# ATmega168PA device description
Architecture: AVR8; Family: megaAVR
Registers are 8-bit, access not given, no defined reset value unless marked. A register's access mark holds for its fields unless they carry their own. Offsets are from the block's base; [hi:lo] are bit positions; {n}, {i} and the like mark numbered series.

## TC2 (TC8_ASYNC module) — Timer/Counter, 8-bit Async
Instances: TC2 0x00
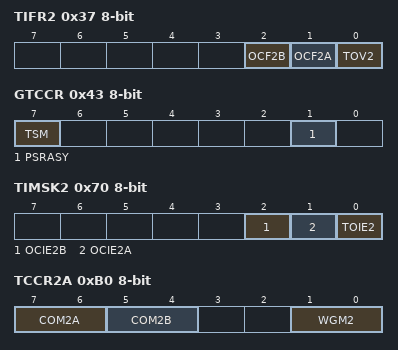
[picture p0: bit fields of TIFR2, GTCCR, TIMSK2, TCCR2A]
0x37 TIFR2 — Timer/Counter Interrupt Flag Register
  [2] OCF2B — Output Compare Flag 2B
  [1] OCF2A — Output Compare Flag 2A
  [0] TOV2 — Timer/Counter2 Overflow Flag
0x43 GTCCR — General Timer Counter Control register
  [7] TSM — Timer/Counter Synchronization Mode
  [1] PSRASY — Prescaler Reset Timer/Counter2
0x70 TIMSK2 — Timer/Counter Interrupt Mask register
  [2] OCIE2B — Timer/Counter2 Output Compare Match B Interrupt Enable
  [1] OCIE2A — Timer/Counter2 Output Compare Match A Interrupt Enable
  [0] TOIE2 — Timer/Counter2 Overflow Interrupt Enable
0xB0 TCCR2A — Timer/Counter2 Control Register A
  [7:6] COM2A — Compare Output Mode bits
  [5:4] COM2B — Compare Output Mode bits
  [1:0] WGM2 — Waveform Genration Mode
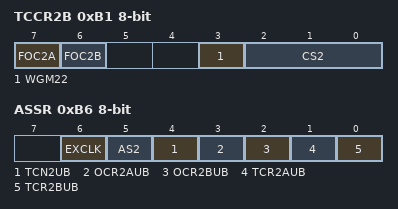
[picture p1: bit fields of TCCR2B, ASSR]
0xB1 TCCR2B — Timer/Counter2 Control Register B
  [7] FOC2A — Force Output Compare A
  [6] FOC2B — Force Output Compare B
  [3] WGM22 — Waveform Generation Mode
  [2:0] CS2 — Clock Select bits
    0=No Clock Source (Stopped); 1=Running, No Prescaling; 2=Running, CLK/8; 3=Running, CLK/32; 4=Running, CLK/64; 5=Running, CLK/128; 6=Running, CLK/256; 7=Running, CLK/1024
0xB2 TCNT2 — Timer/Counter2
0xB3 OCR2A — Timer/Counter2 Output Compare Register A
0xB4 OCR2B — Timer/Counter2 Output Compare Register B
0xB6 ASSR — Asynchronous Status Register
  [6] EXCLK — Enable External Clock Input
  [5] AS2 — Asynchronous Timer/Counter2
  [4] TCN2UB — Timer/Counter2 Update Busy
  [3] OCR2AUB — Output Compare Register2 Update Busy
  [2] OCR2BUB — Output Compare Register 2 Update Busy
  [1] TCR2AUB — Timer/Counter Control Register2 Update Busy
  [0] TCR2BUB — Timer/Counter Control Register2 Update Busy

## ADC — Analog-to-Digital Converter
Instances: ADC 0x00
0x78 ADC 16-bit — ADC Data Register Bytes
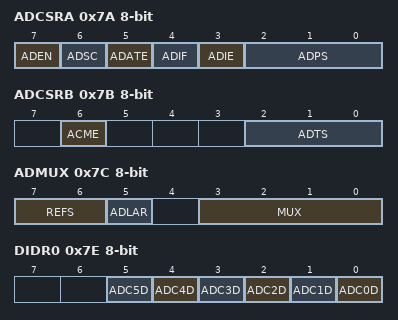
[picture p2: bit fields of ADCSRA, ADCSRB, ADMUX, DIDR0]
0x7A ADCSRA — The ADC Control and Status register A
  [7] ADEN — ADC Enable
  [6] ADSC — ADC Start Conversion
  [5] ADATE — ADC Auto Trigger Enable
  [4] ADIF — ADC Interrupt Flag
  [3] ADIE — ADC Interrupt Enable
  [2:0] ADPS — ADC Prescaler Select Bits
    0=2; 1=2; 2=4; 3=8; 4=16; 5=32; 6=64; 7=128
0x7B ADCSRB — The ADC Control and Status register B
  [6] ACME
  [2:0] ADTS — ADC Auto Trigger Source bits
    0=Free Running mode; 1=Analog Comparator; 2=External Interrupt Request 0; 3=Timer/Counter0 Compare Match A; 4=Timer/Counter0 Overflow; 5=Timer/Counter1 Compare Match B; 6=Timer/Counter1 Overflow; 7=Timer/Counter1 Capture Event
0x7C ADMUX — The ADC multiplexer Selection Register
  [7:6] REFS — Reference Selection Bits
    0=AREF, Internal Vref turned off; 1=AVCC with external capacitor at AREF pin; 3=Internal 1.1V Voltage Reference with external capacitor at AREF pin
  [5] ADLAR — Left Adjust Result
  [3:0] MUX — Analog Channel Selection Bits
    {v}=ADC{v} (ADC Single Ended Input pin {v}) (v=0..7); 8=TEMPSENS (Temperature sensor); 14=ADC_VBG (Internal Reference (VBG)); 15=ADC_GND (0V (GND))
0x7E DIDR0 — Digital Input Disable Register
  [n] ADC{n}D (n=0..5)

## AC — Analog Comparator
Instances: AC 0x00
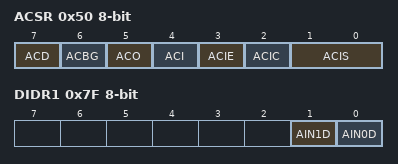
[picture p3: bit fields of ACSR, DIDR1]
0x50 ACSR — Analog Comparator Control And Status Register
  [7] ACD — Analog Comparator Disable
  [6] ACBG — Analog Comparator Bandgap Select
  [5] ACO — Analog Compare Output
  [4] ACI — Analog Comparator Interrupt Flag
  [3] ACIE — Analog Comparator Interrupt Enable
  [2] ACIC — Analog Comparator Input Capture Enable
  [1:0] ACIS — Analog Comparator Interrupt Mode Select bits
    0=Interrupt on Toggle; 2=Interrupt on Falling Edge; 3=Interrupt on Rising Edge
0x7F DIDR1 — Digital Input Disable Register 1
  [1] AIN1D — AIN1 Digital Input Disable
  [0] AIN0D — AIN0 Digital Input Disable

## PORTB — I/O Port
Instances: PORTB 0x00
0x23 PINB — Port B Input Pins
0x24 DDRB — Port B Data Direction Register
0x25 PORTB — Port B Data Register
